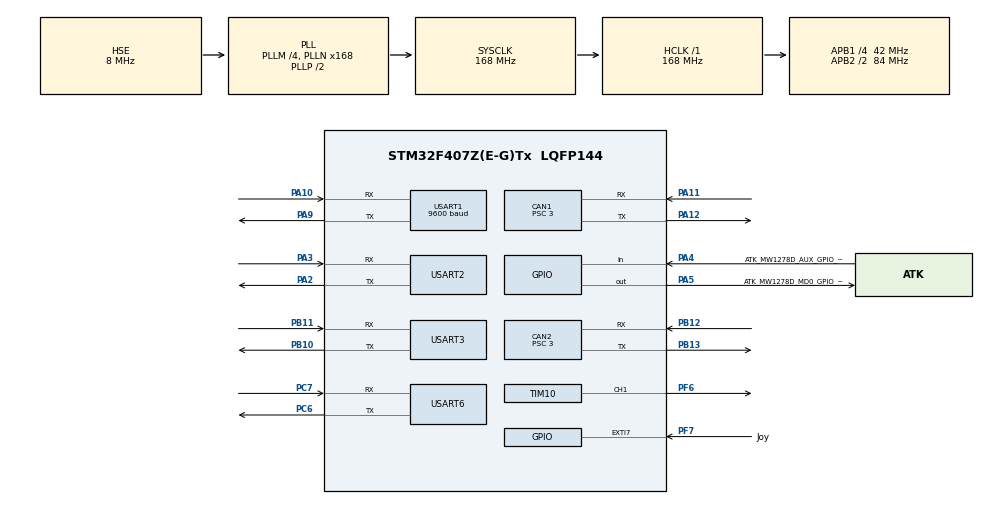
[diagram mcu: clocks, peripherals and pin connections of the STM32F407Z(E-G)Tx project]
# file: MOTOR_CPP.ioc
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CAN1.BS1=CAN_BS1_9TQ
CAN1.BS2=CAN_BS2_4TQ
CAN1.CalculateBaudRate=1000000
CAN1.CalculateTimeBit=1000
CAN1.CalculateTimeQuantum=71.42857142857143
CAN1.Prescaler=3
CAN2.BS1=CAN_BS1_9TQ
CAN2.BS2=CAN_BS2_4TQ
CAN2.CalculateBaudRate=1000000
CAN2.CalculateTimeBit=1000
CAN2.CalculateTimeQuantum=71.42857142857143
CAN2.Prescaler=3
Dma.Request0=USART1_TX
Dma.Request1=USART1_RX
Dma.Request2=USART3_RX
Dma.Request3=USART3_TX
Dma.Request4=USART6_RX
Dma.Request5=USART6_TX
Dma.USART1_RX.1.Direction=DMA_PERIPH_TO_MEMORY
Dma.USART1_RX.1.FIFOMode=DMA_FIFOMODE_DISABLE
Dma.USART1_RX.1.Instance=DMA2_Stream2
Dma.USART1_RX.1.MemDataAlignment=DMA_MDATAALIGN_BYTE
Dma.USART1_RX.1.MemInc=DMA_MINC_ENABLE
Dma.USART1_RX.1.Mode=DMA_NORMAL
Dma.USART1_RX.1.PeriphDataAlignment=DMA_PDATAALIGN_BYTE
Dma.USART1_RX.1.PeriphInc=DMA_PINC_DISABLE
Dma.USART1_RX.1.Priority=DMA_PRIORITY_LOW
Dma.USART1_TX.0.Direction=DMA_MEMORY_TO_PERIPH
Dma.USART1_TX.0.FIFOMode=DMA_FIFOMODE_DISABLE
Dma.USART1_TX.0.Instance=DMA2_Stream7
Dma.USART1_TX.0.MemDataAlignment=DMA_MDATAALIGN_BYTE
Dma.USART1_TX.0.MemInc=DMA_MINC_ENABLE
Dma.USART1_TX.0.Mode=DMA_NORMAL
Dma.USART1_TX.0.PeriphDataAlignment=DMA_PDATAALIGN_BYTE
Dma.USART1_TX.0.PeriphInc=DMA_PINC_DISABLE
Dma.USART1_TX.0.Priority=DMA_PRIORITY_LOW
Dma.USART3_RX.2.Direction=DMA_PERIPH_TO_MEMORY
Dma.USART3_RX.2.FIFOMode=DMA_FIFOMODE_DISABLE
Dma.USART3_RX.2.Instance=DMA1_Stream1
Dma.USART3_RX.2.MemDataAlignment=DMA_MDATAALIGN_BYTE
Dma.USART3_RX.2.MemInc=DMA_MINC_ENABLE
Dma.USART3_RX.2.Mode=DMA_NORMAL
Dma.USART3_RX.2.PeriphDataAlignment=DMA_PDATAALIGN_BYTE
Dma.USART3_RX.2.PeriphInc=DMA_PINC_DISABLE
Dma.USART3_RX.2.Priority=DMA_PRIORITY_LOW
Dma.USART3_TX.3.Direction=DMA_MEMORY_TO_PERIPH
Dma.USART3_TX.3.FIFOMode=DMA_FIFOMODE_DISABLE
Dma.USART3_TX.3.Instance=DMA1_Stream3
Dma.USART3_TX.3.MemDataAlignment=DMA_MDATAALIGN_BYTE
Dma.USART3_TX.3.MemInc=DMA_MINC_ENABLE
Dma.USART3_TX.3.Mode=DMA_NORMAL
Dma.USART3_TX.3.PeriphDataAlignment=DMA_PDATAALIGN_BYTE
Dma.USART3_TX.3.PeriphInc=DMA_PINC_DISABLE
Dma.USART3_TX.3.Priority=DMA_PRIORITY_LOW
Dma.USART6_RX.4.Direction=DMA_PERIPH_TO_MEMORY
Dma.USART6_RX.4.FIFOMode=DMA_FIFOMODE_DISABLE
Dma.USART6_RX.4.Instance=DMA2_Stream1
Dma.USART6_RX.4.MemDataAlignment=DMA_MDATAALIGN_BYTE
Dma.USART6_RX.4.MemInc=DMA_MINC_ENABLE
Dma.USART6_RX.4.Mode=DMA_NORMAL
Dma.USART6_RX.4.PeriphDataAlignment=DMA_PDATAALIGN_BYTE
Dma.USART6_RX.4.PeriphInc=DMA_PINC_DISABLE
Dma.USART6_RX.4.Priority=DMA_PRIORITY_LOW
Dma.USART6_TX.5.Direction=DMA_MEMORY_TO_PERIPH
Dma.USART6_TX.5.FIFOMode=DMA_FIFOMODE_DISABLE
Dma.USART6_TX.5.Instance=DMA2_Stream6
Dma.USART6_TX.5.MemDataAlignment=DMA_MDATAALIGN_BYTE
Dma.USART6_TX.5.MemInc=DMA_MINC_ENABLE
Dma.USART6_TX.5.Mode=DMA_NORMAL
Dma.USART6_TX.5.PeriphDataAlignment=DMA_PDATAALIGN_BYTE
Dma.USART6_TX.5.PeriphInc=DMA_PINC_DISABLE
Dma.USART6_TX.5.Priority=DMA_PRIORITY_LOW
FREERTOS.Tasks01=CAN1_Send,24,128,CAN1_Send_Task,As weak,NULL,Dynamic,NULL,NULL;chassic,40,128,Chassis_Task,As external,NULL,Dynamic,NULL,NULL;CAN2_Send,8,128,CAN2_Send_Task,As external,NULL,Dynamic,NULL,NULL;user_debug,8,128,User_Debug_Task,As external,NULL,Dynamic,NULL,NULL;Air_Joy,8,128,Air_Joy_Task,As external,NULL,Dynamic,NULL,NULL
Mcu.Family=STM32F4
Mcu.Name=STM32F407Z(E-G)Tx
Mcu.Package=LQFP144
NVIC.CAN1_RX0_IRQn=true\:5\:0\:false\:false\:true\:true\:true\:true\:true
NVIC.CAN1_TX_IRQn=true\:5\:0\:false\:false\:true\:true\:true\:true\:true
NVIC.CAN2_RX0_IRQn=true\:5\:0\:false\:false\:true\:true\:true\:true\:true
NVIC.CAN2_TX_IRQn=true\:5\:0\:false\:false\:true\:true\:true\:true\:true
NVIC.DMA1_Stream1_IRQn=true\:5\:0\:false\:false\:true\:true\:false\:true\:true
NVIC.DMA1_Stream3_IRQn=true\:5\:0\:false\:false\:true\:true\:false\:true\:true
NVIC.DMA2_Stream1_IRQn=true\:5\:0\:false\:false\:true\:true\:false\:true\:true
NVIC.DMA2_Stream2_IRQn=true\:5\:0\:false\:false\:true\:true\:false\:true\:true
NVIC.DMA2_Stream6_IRQn=true\:5\:0\:false\:false\:true\:true\:false\:true\:true
NVIC.DMA2_Stream7_IRQn=true\:5\:0\:false\:false\:true\:true\:false\:true\:true
NVIC.EXTI9_5_IRQn=true\:5\:0\:false\:false\:true\:true\:true\:true\:true
NVIC.PriorityGroup=NVIC_PRIORITYGROUP_4
NVIC.TIM3_IRQn=true\:15\:0\:false\:false\:true\:false\:false\:true\:true
NVIC.TIM4_IRQn=true\:5\:0\:false\:false\:true\:true\:true\:true\:true
NVIC.TIM6_DAC_IRQn=true\:5\:0\:false\:false\:true\:true\:true\:true\:true
NVIC.TimeBase=TIM3_IRQn
NVIC.TimeBaseIP=TIM3
NVIC.USART1_IRQn=true\:5\:0\:false\:false\:true\:true\:true\:true\:true
NVIC.USART3_IRQn=true\:5\:0\:false\:false\:true\:true\:true\:true\:true
NVIC.USART6_IRQn=true\:5\:0\:false\:false\:true\:true\:true\:true\:true
PA10.Mode=Asynchronous
PA10.Signal=USART1_RX
PA11.Mode=CAN_Activate
PA11.Signal=CAN1_RX
PA12.Mode=CAN_Activate
PA12.Signal=CAN1_TX
PA13.Mode=Serial_Wire
PA13.Signal=SYS_JTMS-SWDIO
PA14.Mode=Serial_Wire
PA14.Signal=SYS_JTCK-SWCLK
PA2.Mode=Asynchronous
PA2.Signal=USART2_TX
PA3.Mode=Asynchronous
PA3.Signal=USART2_RX
PA4.GPIO_Label=ATK_MW1278D_AUX_GPIO_PIN
PA4.GPIO_PuPd=GPIO_PULLUP
PA4.Signal=GPIO_Input
PA5.GPIO_Label=ATK_MW1278D_MD0_GPIO_PIN
PA5.GPIO_PuPd=GPIO_PULLDOWN
PA5.GPIO_Speed=GPIO_SPEED_FREQ_HIGH
PA5.Signal=GPIO_Output
PA9.Mode=Asynchronous
PA9.Signal=USART1_TX
PB10.Mode=Asynchronous
PB10.Signal=USART3_TX
PB11.Mode=Asynchronous
PB11.Signal=USART3_RX
PB12.Mode=CAN_Activate
PB12.Signal=CAN2_RX
PB13.Mode=CAN_Activate
PB13.Signal=CAN2_TX
PC14-OSC32_IN.Mode=LSE-External-Oscillator
PC14-OSC32_IN.Signal=RCC_OSC32_IN
PC15-OSC32_OUT.Mode=LSE-External-Oscillator
PC15-OSC32_OUT.Signal=RCC_OSC32_OUT
PC6.Mode=Asynchronous
PC6.Signal=USART6_TX
PC7.Mode=Asynchronous
PC7.Signal=USART6_RX
PF6.Signal=S_TIM10_CH1
PF7.GPIO_Label=Joy
PF7.Signal=GPXTI7
PH0-OSC_IN.Mode=HSE-External-Oscillator
PH0-OSC_IN.Signal=RCC_OSC_IN
PH1-OSC_OUT.Mode=HSE-External-Oscillator
PH1-OSC_OUT.Signal=RCC_OSC_OUT
ProjectManager.HeapSize=0x200
ProjectManager.StackSize=0x400
ProjectManager.TargetToolchain=MDK-ARM V5.32
RCC.48MHZClocksFreq_Value=84000000
RCC.AHBFreq_Value=168000000
RCC.APB1CLKDivider=RCC_HCLK_DIV4
RCC.APB1Freq_Value=42000000
RCC.APB1TimFreq_Value=84000000
RCC.APB2CLKDivider=RCC_HCLK_DIV2
RCC.APB2Freq_Value=84000000
RCC.APB2TimFreq_Value=168000000
RCC.CortexFreq_Value=168000000
RCC.HCLKFreq_Value=168000000
RCC.HSE_VALUE=8000000
RCC.HSI_VALUE=16000000
RCC.PLLM=4
RCC.PLLN=168
RCC.PLLSourceVirtual=RCC_PLLSOURCE_HSE
RCC.SYSCLKFreq_VALUE=168000000
RCC.SYSCLKSource=RCC_SYSCLKSOURCE_PLLCLK
RCC.VCOOutputFreq_Value=336000000
SH.S_TIM10_CH1.0=TIM10_CH1,PWM Generation1 CH1
TIM10.Channel=TIM_CHANNEL_1
TIM10.Period=2099
TIM10.Prescaler=83
TIM4.Prescaler=83
USART1.BaudRate=9600
USART1.VirtualMode=VM_ASYNC
USART2.VirtualMode=VM_ASYNC
USART3.VirtualMode=VM_ASYNC
USART6.VirtualMode=VM_ASYNC
VP_FREERTOS_VS_CMSIS_V2.Mode=CMSIS_V2
VP_SYS_VS_tim3.Mode=TIM3
VP_TIM10_VS_ClockSourceINT.Mode=Enable_Timer
VP_TIM4_VS_ClockSourceINT.Mode=Internal
VP_TIM6_VS_ClockSourceINT.Mode=Enable_Timer
board=custom

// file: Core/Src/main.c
/* USER CODE BEGIN Header */
/**
  ******************************************************************************
  * @file           : main.c
  * @brief          : Main program body
  ******************************************************************************
  * @attention
  *
  * Copyright (c) 2024 STMicroelectronics.
  * All rights reserved.
  *
  * This software is licensed under terms that can be found in the LICENSE file
  * in the root directory of this software component.
  * If no LICENSE file comes with this software, it is provided AS-IS.
  *
  ******************************************************************************
  */
/* USER CODE END Header */
#include "main.h"
#include "cmsis_os.h"
#include "can.h"
#include "dma.h"
#include "tim.h"
#include "usart.h"
#include "gpio.h"

/* USER CODE BEGIN Includes */
#include "service_config.h"
#include "atk_mw1278d.h"
/* USER CODE END Includes */

void SystemClock_Config(void);
void MX_FREERTOS_Init(void);

int main(void)
{

  /* MCU Configuration--------------------------------------------------------*/

  /* Reset of all peripherals, Initializes the Flash interface and the Systick. */
  HAL_Init();

  /* Configure the system clock */
  SystemClock_Config();

  /* Initialize all configured peripherals */
  MX_GPIO_Init();
  MX_DMA_Init();
  MX_CAN1_Init();
  MX_CAN2_Init();
  MX_USART1_UART_Init();
  MX_USART2_UART_Init();
  MX_USART3_UART_Init();
  MX_USART6_UART_Init();
  MX_TIM4_Init();
  MX_TIM10_Init();
  MX_TIM6_Init();
  /* USER CODE BEGIN 2 */
  System_Resource_Init();
  /* USER CODE END 2 */

  /* Init scheduler */
  osKernelInitialize();

  /* Call init function for freertos objects (in cmsis_os2.c) */
  MX_FREERTOS_Init();

  /* Start scheduler */
  osKernelStart();
  /* We should never get here as control is now taken by the scheduler */

  /* Infinite loop */
  while (1)
  {

  }
}

void SystemClock_Config(void)
{
  RCC_OscInitTypeDef RCC_OscInitStruct = {0};
  RCC_ClkInitTypeDef RCC_ClkInitStruct = {0};

  /** Configure the main internal regulator output voltage
  */
  __HAL_RCC_PWR_CLK_ENABLE();
  __HAL_PWR_VOLTAGESCALING_CONFIG(PWR_REGULATOR_VOLTAGE_SCALE1);

  /** Initializes the RCC Oscillators according to the specified parameters
  * in the RCC_OscInitTypeDef structure.
  */
  RCC_OscInitStruct.OscillatorType = RCC_OSCILLATORTYPE_HSE;
  RCC_OscInitStruct.HSEState = RCC_HSE_ON;
  RCC_OscInitStruct.PLL.PLLState = RCC_PLL_ON;
  RCC_OscInitStruct.PLL.PLLSource = RCC_PLLSOURCE_HSE;
  RCC_OscInitStruct.PLL.PLLM = 4;
  RCC_OscInitStruct.PLL.PLLN = 168;
  RCC_OscInitStruct.PLL.PLLP = RCC_PLLP_DIV2;
  RCC_OscInitStruct.PLL.PLLQ = 4;
  if (HAL_RCC_OscConfig(&RCC_OscInitStruct) != HAL_OK)
  {
    Error_Handler();
  }

  /** Initializes the CPU, AHB and APB buses clocks
  */
  RCC_ClkInitStruct.ClockType = RCC_CLOCKTYPE_HCLK|RCC_CLOCKTYPE_SYSCLK
                              |RCC_CLOCKTYPE_PCLK1|RCC_CLOCKTYPE_PCLK2;
  RCC_ClkInitStruct.SYSCLKSource = RCC_SYSCLKSOURCE_PLLCLK;
  RCC_ClkInitStruct.AHBCLKDivider = RCC_SYSCLK_DIV1;
  RCC_ClkInitStruct.APB1CLKDivider = RCC_HCLK_DIV4;
  RCC_ClkInitStruct.APB2CLKDivider = RCC_HCLK_DIV2;

  if (HAL_RCC_ClockConfig(&RCC_ClkInitStruct, FLASH_LATENCY_5) != HAL_OK)
  {
    Error_Handler();
  }
}

void HAL_TIM_PeriodElapsedCallback(TIM_HandleTypeDef *htim)
{
  if (htim->Instance == TIM3)
  {
    HAL_IncTick();
  }
  /* USER CODE BEGIN Callback 1 */
  if(htim->Instance == TIM4)
  {
    Update_SystemTick();
  }
  /* USER CODE END Callback 1 */
}

void Error_Handler(void)
{
  __disable_irq();
  while (1)
  {
  }
}

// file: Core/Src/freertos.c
/* USER CODE BEGIN Header */
/**
  ******************************************************************************
  * File Name          : freertos.c
  * Description        : Code for freertos applications
  ******************************************************************************
  * @attention
  *
  * Copyright (c) 2024 STMicroelectronics.
  * All rights reserved.
  *
  * This software is licensed under terms that can be found in the LICENSE file
  * in the root directory of this software component.
  * If no LICENSE file comes with this software, it is provided AS-IS.
  *
  ******************************************************************************
  */
/* USER CODE END Header */

#include "FreeRTOS.h"
#include "task.h"
#include "main.h"
#include "cmsis_os.h"
extern void Lora_Task(void *argument);

/* Definitions for CAN1_Send */
//osThreadId_t CAN1_SendHandle;
//const osThreadAttr_t CAN1_Send_attributes = {
//  .name = "CAN1_Send",
//  .stack_size = 128 * 4,
//  .priority = (osPriority_t) osPriorityNormal,
//};
/* Definitions for chassic */
osThreadId_t chassicHandle;
const osThreadAttr_t chassic_attributes = {
  .name = "chassic",
  .stack_size = 128 * 4,
  .priority = (osPriority_t) osPriorityHigh,
};
/* Definitions for CAN2_Send */
osThreadId_t CAN2_SendHandle;
const osThreadAttr_t CAN2_Send_attributes = {
  .name = "CAN2_Send",
  .stack_size = 128 * 4,
  .priority = (osPriority_t) osPriorityLow,
};
/* Definitions for user_debug */
osThreadId_t user_debugHandle;
const osThreadAttr_t user_debug_attributes = {
  .name = "user_debug",
  .stack_size = 128 * 4,
  .priority = (osPriority_t) osPriorityLow,
};
/* Definitions for Air_Joy */
osThreadId_t Air_JoyHandle;
const osThreadAttr_t Air_Joy_attributes = {
  .name = "Air_Joy",
  .stack_size = 128 * 4,
  .priority = (osPriority_t) osPriorityLow,
};

osThreadId_t loraTask1Handle;
/* Definitions for lora_task */
const osThreadAttr_t lora_attributes1 = {
  .name = "Lora_Task1",
  .stack_size = 70*4,
  .priority = (osPriority_t) osPriorityNormal,
};
/* Definitions for lora_task */osThreadId_t loraTaskHandle;
const osThreadAttr_t lora_attributes = {
  .name = "lora_task",
  .stack_size = 70*4,
  .priority = (osPriority_t) osPriorityNormal,
};

void CAN1_Send_Task(void *argument);
extern void Chassis_Task(void *argument);
extern void CAN2_Send_Task(void *argument);
extern void User_Debug_Task(void *argument);
extern void Air_Joy_Task(void *argument);
void Lora_Task1(void *argument);
void MX_FREERTOS_Init(void); /* (MISRA C 2004 rule 8.1) */

void MX_FREERTOS_Init(void) {

  /* Create the thread(s) */
  /* creation of lora_task */
  loraTaskHandle = osThreadNew(Lora_Task, NULL, &lora_attributes);

    /* creation of lora_task */
  loraTask1Handle = osThreadNew(Lora_Task1, NULL, &lora_attributes1);
  /* creation of CAN1_Send */
//  CAN1_SendHandle = osThreadNew(CAN1_Send_Task, NULL, &CAN1_Send_attributes);

  /* creation of chassic */
  chassicHandle = osThreadNew(Chassis_Task, NULL, &chassic_attributes);

  /* creation of CAN2_Send */
  CAN2_SendHandle = osThreadNew(CAN2_Send_Task, NULL, &CAN2_Send_attributes);

  /* creation of user_debug */
  user_debugHandle = osThreadNew(User_Debug_Task, NULL, &user_debug_attributes);

  /* creation of Air_Joy */
  Air_JoyHandle = osThreadNew(Air_Joy_Task, NULL, &Air_Joy_attributes);

}

__weak void CAN1_Send_Task(void *argument)
{
  for(;;)
  {
    osDelay(1);
  }
}
